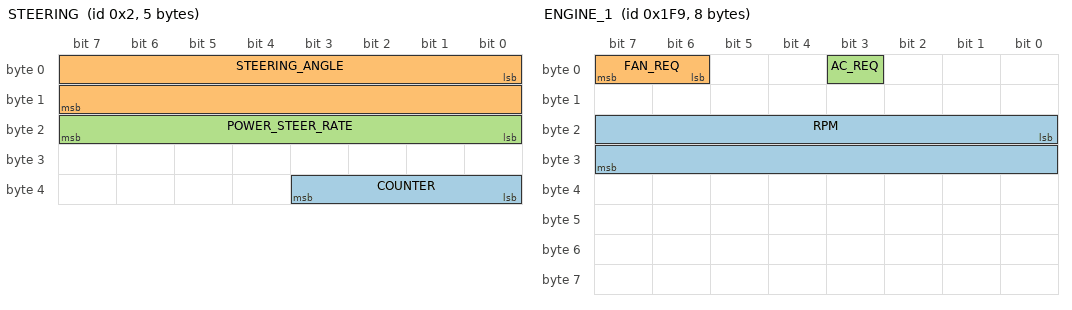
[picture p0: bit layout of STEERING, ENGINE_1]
BO_ 2 STEERING: 5 XXX
 SG_ COUNTER : 35|4@0+ (1,0) [0|255] "" XXX
 SG_ STEERING_ANGLE : 0|16@1- (0.1,0) [0|65535] "deg" XXX
 SG_ POWER_STEER_RATE : 23|8@0+ (1,0) [0|255] "" XXX

BO_ 505 ENGINE_1: 8 XXX
 SG_ RPM : 16|16@1+ (0.125,0) [0|45000] "R/min" XXX
 SG_ FAN_REQ : 6|2@1+ (1,0) [0|3] "" XXX
 SG_ AC_REQ : 3|1@1+ (1,0) [0|1] "" XXX

BO_ 561 ENGINE_2: 8 XXX
 SG_ Pedal_position : 16|8@1+ (0.5,0) [0|200] "%" XXX

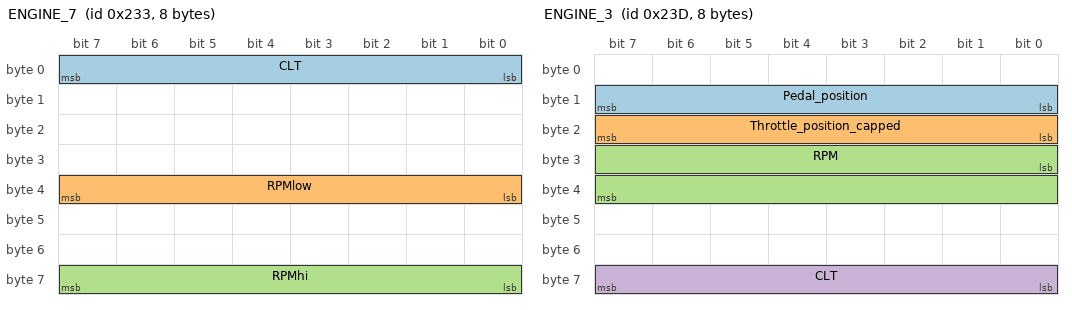
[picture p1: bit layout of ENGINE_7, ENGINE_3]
BO_ 563 ENGINE_7: 8 XXX
 SG_ CLT : 0|8@1+ (0.366666,0) [0|255] "C" XXX
 SG_ RPMlow : 32|8@1+ (3.15,0) [0|45000] "R/min" XXX
 SG_ RPMhi : 56|8@1+ (3.15,0) [0|45000] "R/min" XXX

BO_ 573 ENGINE_3: 8 XXX
 SG_ Pedal_position : 8|8@1+ (0.392,0) [0|255] "%" XXX
 SG_ Throttle_position_capped : 16|8@1+ (0.392,0) [0|255] "%" XXX
 SG_ RPM : 24|16@1+ (3.15,0) [0|45000] "R/min" XXX
 SG_ CLT : 56|8@1+ (0.366666,0) [0|255] "C" XXX

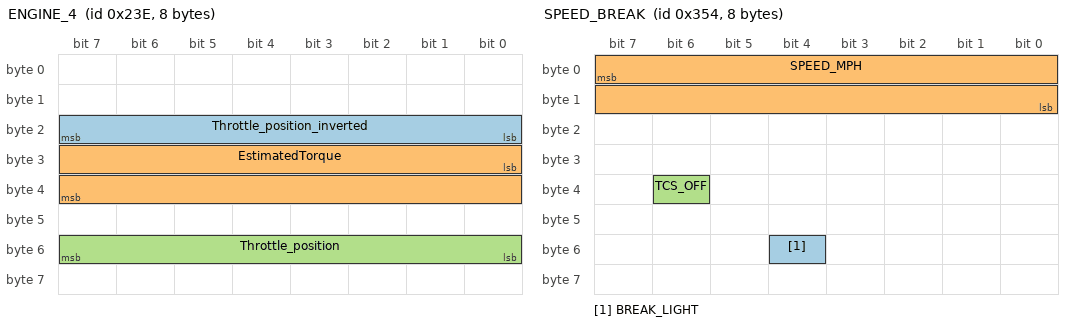
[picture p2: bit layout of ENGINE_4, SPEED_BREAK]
BO_ 574 ENGINE_4: 8 XXX
 SG_ Throttle_position_inverted : 16|8@1+ (0.392,0) [0|255] "%" XXX
 SG_ EstimatedTorque : 24|16@1+ (0.1,0) [0|45000] "nM" XXX
 SG_ Throttle_position : 48|8@1+ (0.392,0) [0|255] "%" XXX

BO_ 595 TCU_1: 8 XXX
 SG_ SHAFT_1_SPEED : 32|16@1+ (1,0) [0|45000] "r/min" XXX
 SG_ SHAFT_2_SPEED : 48|16@1+ (1,0) [0|45000] "r/min" XXX

BO_ 640 SPEED: 8 XXX
 SG_ SPEED : 32|16@1+ (0.01,0) [0|45000] "km/h" XXX

BO_ 644 ABS_1: 8 XXX
 SG_ WHEEL_1 : 0|16@1+ (0.01,0) [0|45000] "km/h" XXX
 SG_ WHEEL_2 : 15|16@1+ (0.01,0) [0|45000] "km/h" XXX

BO_ 645 ABS_2: 8 XXX
 SG_ WHEEL_3 : 0|16@1+ (0.01,0) [0|45000] "km/h" XXX
 SG_ WHEEL_4 : 15|16@1+ (0.01,0) [0|45000] "km/h" XXX

BO_ 852 SPEED_BREAK: 8 XXX
 SG_ BREAK_LIGHT : 52|1@0+ (1,0) [0|3] "" XXX
 SG_ SPEED_MPH : 7|16@0+ (0.0066,0) [0|65535] "mph" XXX
 SG_ TCS_OFF : 38|1@0+ (1,0) [0|255] "" XXX

BO_ 861 BCM: 8 XXX

BO_ 1361 ENGINE_5: 8 XXX
 SG_ CLT : 0|8@1+ (1,-45) [-45|150] "" XXX

BO_ 1408 ENGINE_6: 8 XXX
 SG_ RPM : 7|16@0+ (1.5,0) [0|65535] "" XXX
 SG_ OIL_TEMP : 32|8@1+ (1,-40) [-40|150] "" XXX

BU_: XXX

CM_ "AUTOGENERATED FILE, DO NOT EDIT";

CM_ "Imported file _honda_common.dbc starts here";
CM_ SG_ 304 "Seems to be platform-agnostic";
CM_ SG_ 316 "Should exist on Nidec";
CM_ SG_ 420 BRAKE_HOLD_RELATED "On when Brake Hold engaged";
CM_ SG_ 490 LONG_ACCEL "wheel speed derivative, noisy and zero snapping";
CM_ SG_ 773 PASS_AIRBAG_ON "Might just be indicator light";
CM_ SG_ 773 PASS_AIRBAG_OFF "Might just be indicator light";
CM_ SG_ 780 CRUISE_SPEED "255 = no speed";
CM_ SG_ 780 PCM_SPEED "Used by Nidec";
CM_ SG_ 780 PCM_GAS "Used by Nidec";
CM_ SG_ 804 CRUISE_SPEED_PCM "255 = no speed";

CM_ "Imported file _bosch_2018.dbc starts here";
CM_ SG_ 450 EPB_STATE "3: On, 2: Disengaging, 1: Engaging, 0: Off";
CM_ SG_ 576 LINE_DISTANCE_VISIBLE "Length of line visible, undecoded";
CM_ SG_ 577 LINE_FAR_EDGE_POSITION "Appears to be a measure of line thickness, indicates location of the portion of the line furthest from the car, undecoded";
CM_ SG_ 577 LINE_PARAMETER "Unclear if this is low quality line curvature rate or if this is something else, but it is correlated with line curvature, undecoded";
CM_ SG_ 577 LINE_DASHED "1 = line is dashed";
CM_ SG_ 577 LINE_SOLID "1 = line is solid";

CM_ "Imported file _bosch_adas_2018.dbc starts here";
CM_ SG_ 479 CONTROL_ON "Set to 5 when car is being controlled";
CM_ SG_ 479 AEB_STATUS "set for the duration of AEB event";
CM_ SG_ 479 AEB_BRAKING "set when braking is commanded during AEB event";
CM_ SG_ 479 AEB_PREPARE "set 1s before AEB";
CM_ SG_ 829 BEEP "beeps are pleasant, chimes are for warnngs etc...";

CM_ "Imported file _steering_sensors_a.dbc starts here";
CM_ "honda_civic_hatchback_ex_2017_can.dbc starts here";

VAL_ 513 STATE 5 "FAULT_TIMEOUT" 4 "FAULT_STARTUP" 3 "FAULT_SCE" 2 "FAULT_SEND" 1 "FAULT_BAD_CHECKSUM" 0 "NO_FAULT" ;

VAL_ 780 CRUISE_SPEED 255 "no_speed" 252 "stopped";
VAL_ 780 HUD_LEAD 3 "acc_off" 2 "solid_car" 1 "dashed_car" 0 "no_car";
VAL_ 884 DASHBOARD_ALERT 0 "none" 51 "acc_problem" 55 "cmbs_problem" 75 "key_not_detected" 79 "fasten_seatbelt" 111 "lkas_problem" 131 "brake_system_problem" 132 "brake_hold_problem" 139 "tbd" 161 "door_open";
VAL_ 891 WIPERS 4 "High" 2 "Low" 0 "Off";

VAL_ 506 FCW 3 "fcw" 2 "fcw" 1 "fcw" 0 "no_fcw";
VAL_ 506 CHIME 4 "double_chime" 3 "single_chime" 2 "continuous_chime" 1 "repeating_chime" 0 "no_chime";
VAL_ 506 AEB_STATUS 3 "aeb_prepare" 2 "aeb_ready" 1 "aeb_braking" 0 "no_aeb";
VAL_ 829 BEEP 3 "single_beep" 2 "triple_beep" 1 "repeated_beep" 0 "no_beep";

VAL_ 399 STEER_STATUS 5 "tmp_fault" 4 "no_torque_alert_2" 2 "no_torque_alert_1" 0 "normal" ;
VAL_ 419 GEAR_SHIFTER 10 "S" 4 "D" 3 "N" 2 "R" 1 "P" ;
VAL_ 450 EPB_STATE 3 "engaged" 2 "disengaging" 1 "engaging" 0 "disengaged" ;
VAL_ 545 ECON_ON_2 0 "off" 3 "on" ;
VAL_ 662 CRUISE_BUTTONS 7 "tbd" 6 "tbd" 5 "tbd" 4 "accel_res" 3 "decel_set" 2 "cancel" 1 "main" 0 "none" ;
VAL_ 662 CRUISE_SETTING 3 "distance_adj" 2 "tbd" 1 "lkas_button" 0 "none" ;
VAL_ 806 CMBS_BUTTON 3 "pressed" 0 "released" ;
